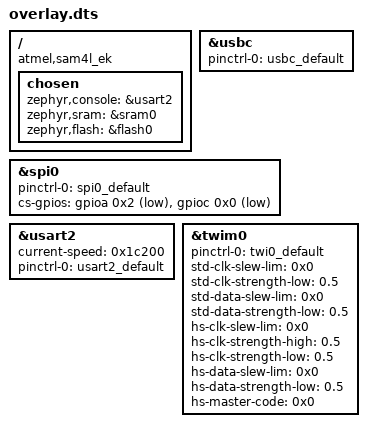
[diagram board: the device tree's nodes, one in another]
/ {
	compatible = "atmel,sam4l_ek";
	chosen {
		zephyr,console = &usart2;
		zephyr,sram = &sram0;
		zephyr,flash = &flash0;
	};
};
&usbc{
	status = "okay";
	pinctrl-0 = < &usbc_default >;
	pinctrl-names = "default";
};
&spi0{
	status = "okay";
	pinctrl-0 = < &spi0_default >;
	pinctrl-names = "default";
	cs-gpios = < &gpioa 0x2 0x1 >, < &gpioc 0x0 0x1 >;
};
&usart2{
	status = "okay";
	current-speed = < 0x1c200 >;
	pinctrl-0 = < &usart2_default >;
	pinctrl-names = "default";
};
&twim0{
	status = "okay";
	pinctrl-0 = < &twi0_default >;
	pinctrl-names = "default";
	std-clk-slew-lim = < 0x0 >;
	std-clk-strength-low = "0.5";
	std-data-slew-lim = < 0x0 >;
	std-data-strength-low = "0.5";
	hs-clk-slew-lim = < 0x0 >;
	hs-clk-strength-high = "0.5";
	hs-clk-strength-low = "0.5";
	hs-data-slew-lim = < 0x0 >;
	hs-data-strength-low = "0.5";
	hs-master-code = < 0x0 >;
};
